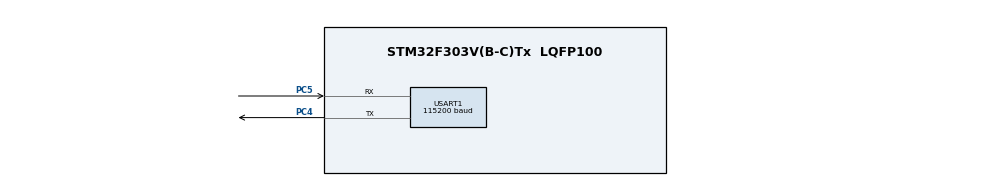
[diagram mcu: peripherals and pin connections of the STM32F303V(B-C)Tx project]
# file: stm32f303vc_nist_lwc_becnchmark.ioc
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Mcu.Family=STM32F3
RCC.CortexFreq_Value=16000000
USART1.BaudRate=115200
RCC.SYSCLKSourceVirtual=RCC_SYSCLKSOURCE_PLLCLK
PC4.Signal=USART1_TX
PC5.Mode=Asynchronous
RCC.APB1CLKDivider=RCC_HCLK_DIV2
ProjectManager.StackSize=0x400
USART1.VirtualMode-Asynchronous=VM_ASYNC
PA13.Signal=SYS_JTMS-SWDIO
ProjectManager.TargetToolchain=STM32CubeIDE
RCC.HCLKFreq_Value=16000000
RCC.APB2TimFreq_Value=16000000
RCC.USBFreq_Value=16000000
RCC.LSE_VALUE=32768
RCC.AHBFreq_Value=16000000
RCC.HSE_VALUE=8000000
board=custom
RCC.PLLMUL=RCC_PLL_MUL4
RCC.APB2Freq_Value=16000000
VP_TIM2_VS_ClockSourceINT.Mode=Internal
PA14.Mode=Serial_Wire
PA13.Mode=Serial_Wire
Mcu.Name=STM32F303V(B-C)Tx
RCC.SYSCLKFreq_VALUE=16000000
Mcu.Package=LQFP100
PA14.Signal=SYS_JTCK-SWCLK
ProjectManager.HeapSize=0x200
RCC.HSI_VALUE=8000000
NVIC.PriorityGroup=NVIC_PRIORITYGROUP_4
RCC.APB1TimFreq_Value=16000000
PC5.Signal=USART1_RX
RCC.APB1Freq_Value=8000000
PC4.Mode=Asynchronous

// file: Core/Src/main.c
/* USER CODE BEGIN Header */
/**
  ******************************************************************************
  * @file           : main.c
  * @brief          : Main program body
  ******************************************************************************
  * @attention
  *
  * <h2><center>&copy; Copyright (c) 2021 STMicroelectronics.
  * All rights reserved.</center></h2>
  *
  * This software component is licensed by ST under BSD 3-Clause license,
  * the "License"; You may not use this file except in compliance with the
  * License. You may obtain a copy of the License at:
  *                        opensource.org/licenses/BSD-3-Clause
  *
  ******************************************************************************
  */
/* USER CODE END Header */
#include "main.h"

/* USER CODE BEGIN Includes */
#include "lwc_config.h"
/* USER CODE END Includes */

UART_HandleTypeDef huart1;

void SystemClock_Config(void);
static void MX_GPIO_Init(void);
static void MX_TIM2_Init(void);
static void MX_USART1_UART_Init(void);

/* USER CODE BEGIN 0 */

int genkat_aead_funct(void);

uint32_t tim_ticks[4];
int tim_ticks_pos = 0;

/* USER CODE END 0 */

int main(void)
{

  /* MCU Configuration--------------------------------------------------------*/

  /* Reset of all peripherals, Initializes the Flash interface and the Systick. */
  HAL_Init();

  /* Configure the system clock */
  SystemClock_Config();

  /* Initialize all configured peripherals */
  MX_GPIO_Init();
  MX_TIM2_Init();
  MX_USART1_UART_Init();

  /* Infinite loop */
  /* USER CODE BEGIN WHILE */
  while (1)
  {

	  LL_TIM_SetCounter(TIM2, 0);
	  LL_TIM_EnableCounter(TIM2);

	  /* Algorithm starts */
	  int res = genkat_aead_funct();

	  if(res != 0 ){
		  LL_mDelay(100000000);
	  }
	  /* Algorithm ends */

	  LL_TIM_DisableCounter(TIM2);
	  tim_ticks[tim_ticks_pos] = LL_TIM_GetCounter(TIM2);

	  tim_ticks_pos++;
	  if(tim_ticks_pos >= sizeof(tim_ticks)/sizeof(tim_ticks[0]) ){
		  tim_ticks_pos = 0;
	  }

	  LL_mDelay(1000000);

	  //LL_USART_TransmitData8(USART1, 'h');

    /* USER CODE END WHILE */

  }
}

void SystemClock_Config(void)
{
  LL_FLASH_SetLatency(LL_FLASH_LATENCY_0);
  while(LL_FLASH_GetLatency()!= LL_FLASH_LATENCY_0)
  {
  }
  LL_RCC_HSI_Enable();

   /* Wait till HSI is ready */
  while(LL_RCC_HSI_IsReady() != 1)
  {

  }
  LL_RCC_HSI_SetCalibTrimming(16);
  LL_RCC_PLL_ConfigDomain_SYS(LL_RCC_PLLSOURCE_HSI_DIV_2, LL_RCC_PLL_MUL_4);
  LL_RCC_PLL_Enable();

   /* Wait till PLL is ready */
  while(LL_RCC_PLL_IsReady() != 1)
  {

  }
  LL_RCC_SetAHBPrescaler(LL_RCC_SYSCLK_DIV_1);
  LL_RCC_SetAPB1Prescaler(LL_RCC_APB1_DIV_2);
  LL_RCC_SetAPB2Prescaler(LL_RCC_APB1_DIV_1);
  LL_RCC_SetSysClkSource(LL_RCC_SYS_CLKSOURCE_PLL);

   /* Wait till System clock is ready */
  while(LL_RCC_GetSysClkSource() != LL_RCC_SYS_CLKSOURCE_STATUS_PLL)
  {

  }
  LL_SetSystemCoreClock(16000000);

   /* Update the time base */
  if (HAL_InitTick (TICK_INT_PRIORITY) != HAL_OK)
  {
    Error_Handler();
  }
  LL_RCC_SetUSARTClockSource(LL_RCC_USART1_CLKSOURCE_PCLK2);
}

static void MX_TIM2_Init(void)
{

  LL_TIM_InitTypeDef TIM_InitStruct = {0};

  /* Peripheral clock enable */
  LL_APB1_GRP1_EnableClock(LL_APB1_GRP1_PERIPH_TIM2);

  TIM_InitStruct.Prescaler = 0;
  TIM_InitStruct.CounterMode = LL_TIM_COUNTERMODE_UP;
  TIM_InitStruct.Autoreload = 4294967295;
  TIM_InitStruct.ClockDivision = LL_TIM_CLOCKDIVISION_DIV1;
  LL_TIM_Init(TIM2, &TIM_InitStruct);
  LL_TIM_DisableARRPreload(TIM2);
  LL_TIM_SetClockSource(TIM2, LL_TIM_CLOCKSOURCE_INTERNAL);
  LL_TIM_SetTriggerOutput(TIM2, LL_TIM_TRGO_RESET);
  LL_TIM_DisableMasterSlaveMode(TIM2);

}

static void MX_USART1_UART_Init(void)
{

  huart1.Instance = USART1;
  huart1.Init.BaudRate = 115200;
  huart1.Init.WordLength = UART_WORDLENGTH_8B;
  huart1.Init.StopBits = UART_STOPBITS_1;
  huart1.Init.Parity = UART_PARITY_NONE;
  huart1.Init.Mode = UART_MODE_TX_RX;
  huart1.Init.HwFlowCtl = UART_HWCONTROL_NONE;
  huart1.Init.OverSampling = UART_OVERSAMPLING_16;
  huart1.Init.OneBitSampling = UART_ONE_BIT_SAMPLE_DISABLE;
  huart1.AdvancedInit.AdvFeatureInit = UART_ADVFEATURE_NO_INIT;
  if (HAL_UART_Init(&huart1) != HAL_OK)
  {
    Error_Handler();
  }

}

static void MX_GPIO_Init(void)
{

  /* GPIO Ports Clock Enable */
  LL_AHB1_GRP1_EnableClock(LL_AHB1_GRP1_PERIPH_GPIOC);
  LL_AHB1_GRP1_EnableClock(LL_AHB1_GRP1_PERIPH_GPIOA);

}

void Error_Handler(void)
{
  __disable_irq();
  while (1)
  {
  }
}

/************************ (C) COPYRIGHT STMicroelectronics *****END OF FILE****/
